VERSION ""

NS_ :

BS_:

BU_: XXX

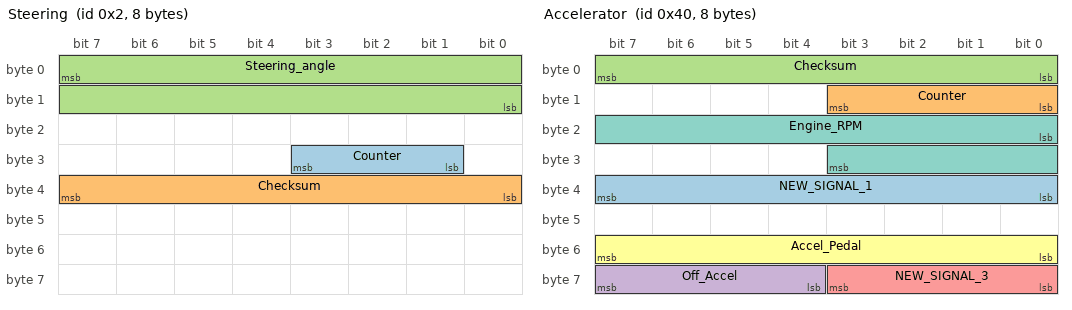
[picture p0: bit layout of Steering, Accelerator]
BO_ 2 Steering: 8 XXX
 SG_ Counter : 25|3@1+ (1,0) [0|7] "" XXX
 SG_ Checksum : 39|8@0+ (1,0) [0|255] "" XXX
 SG_ Steering_angle : 7|16@0- (1,0) [0|65535] "" XXX

BO_ 64 Accelerator: 8 XXX
 SG_ NEW_SIGNAL_1 : 32|8@1+ (1,0) [0|255] "" XXX
 SG_ Counter : 11|4@0+ (1,0) [0|255] "" XXX
 SG_ Checksum : 7|8@0- (1,0) [0|255] "" XXX
 SG_ Off_Accel : 63|4@0+ (1,0) [0|7] "" XXX
 SG_ NEW_SIGNAL_3 : 56|4@1+ (1,0) [0|255] "" XXX
 SG_ Accel_Pedal : 55|8@0+ (1,0) [0|255] "" XXX
 SG_ Engine_RPM : 16|12@1+ (1,0) [0|255] "" XXX

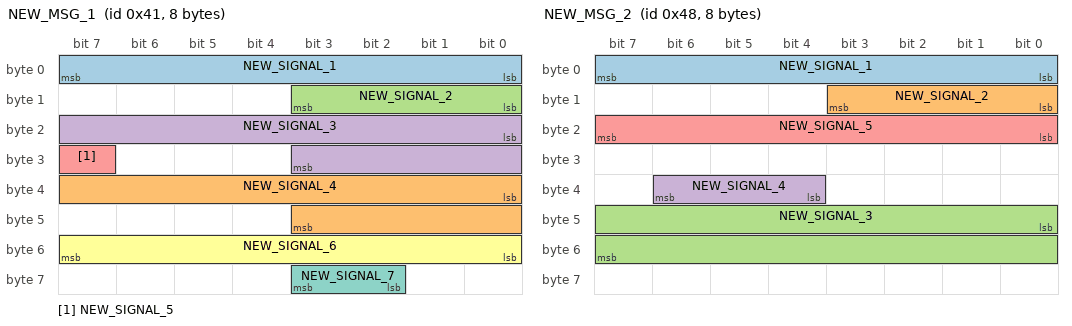
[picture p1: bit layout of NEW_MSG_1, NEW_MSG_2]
BO_ 65 NEW_MSG_1: 8 XXX
 SG_ NEW_SIGNAL_1 : 7|8@0+ (1,0) [0|255] "" XXX
 SG_ NEW_SIGNAL_4 : 32|12@1+ (1,0) [0|255] "" XXX
 SG_ NEW_SIGNAL_2 : 8|4@1+ (1,0) [0|15] "" XXX
 SG_ NEW_SIGNAL_3 : 16|12@1+ (1,0) [0|1] "" XXX
 SG_ NEW_SIGNAL_5 : 31|1@0+ (1,0) [0|15] "" XXX
 SG_ NEW_SIGNAL_6 : 48|8@1+ (1,0) [0|63] "" XXX
 SG_ NEW_SIGNAL_7 : 59|2@0+ (1,0) [0|255] "" XXX

BO_ 72 NEW_MSG_2: 8 XXX
 SG_ NEW_SIGNAL_1 : 7|8@0+ (1,0) [0|255] "" XXX
 SG_ NEW_SIGNAL_2 : 8|4@1+ (1,0) [0|15] "" XXX
 SG_ NEW_SIGNAL_3 : 40|16@1+ (1,0) [0|255] "" XXX
 SG_ NEW_SIGNAL_4 : 38|3@0+ (1,0) [0|255] "" XXX
 SG_ NEW_SIGNAL_5 : 16|8@1+ (1,0) [0|255] "" XXX

BO_ 316 NEW_MSG_3: 8 XXX

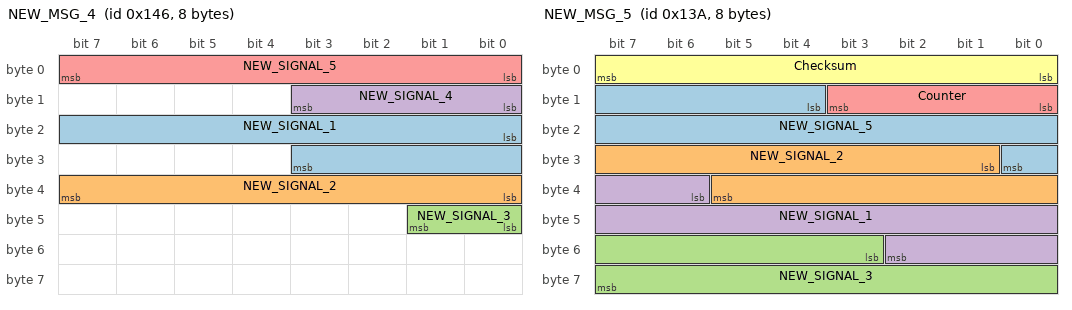
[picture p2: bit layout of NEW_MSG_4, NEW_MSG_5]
BO_ 326 NEW_MSG_4: 8 XXX
 SG_ NEW_SIGNAL_1 : 16|12@1+ (1,0) [0|255] "" XXX
 SG_ NEW_SIGNAL_2 : 32|8@1+ (1,0) [0|255] "" XXX
 SG_ NEW_SIGNAL_3 : 40|2@1+ (1,0) [0|255] "" XXX
 SG_ NEW_SIGNAL_4 : 8|4@1+ (1,0) [0|15] "" XXX
 SG_ NEW_SIGNAL_5 : 7|8@0+ (1,0) [0|255] "" XXX

BO_ 315 G_Sensor: 8 XXX
 SG_ longitudinal : 63|8@0- (1,0) [0|255] "" XXX
 SG_ Latitudinal : 48|8@1- (1,0) [0|255] "" XXX

BO_ 314 NEW_MSG_5: 8 XXX
 SG_ NEW_SIGNAL_5 : 12|13@1+ (1,0) [0|15] "" XXX
 SG_ NEW_SIGNAL_2 : 25|13@1+ (1,0) [0|65535] "" XXX
 SG_ NEW_SIGNAL_3 : 51|13@1+ (1,0) [0|32767] "" XXX
 SG_ NEW_SIGNAL_1 : 38|13@1+ (1,0) [0|63] "" XXX
 SG_ Counter : 8|4@1+ (1,0) [0|15] "" XXX
 SG_ Checksum : 7|8@0+ (1,0) [0|255] "" XXX
